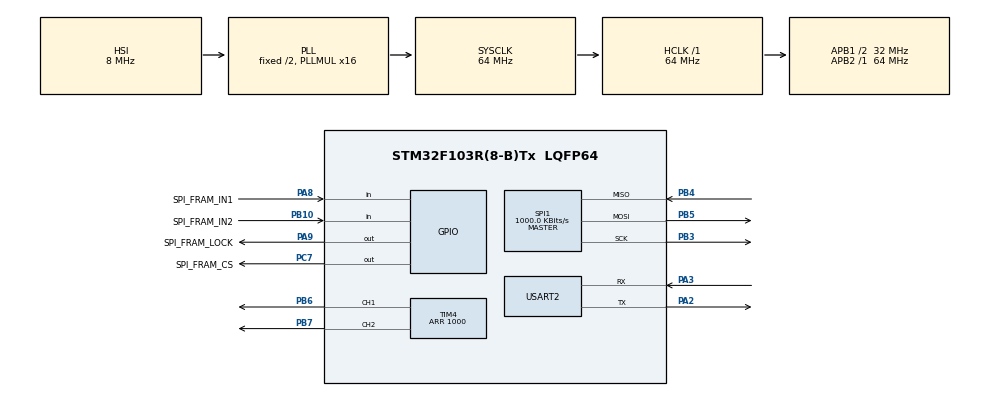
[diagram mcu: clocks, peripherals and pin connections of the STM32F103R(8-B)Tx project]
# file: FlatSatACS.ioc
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Mcu.Family=STM32F1
Mcu.Name=STM32F103R(8-B)Tx
Mcu.Package=LQFP64
NVIC.PriorityGroup=NVIC_PRIORITYGROUP_4
PA2.Mode=Asynchronous
PA2.Signal=USART2_TX
PA3.Mode=Asynchronous
PA3.Signal=USART2_RX
PA8.GPIO_Label=SPI_FRAM_IN1
PA8.Signal=GPIO_Input
PA9.GPIO_Label=SPI_FRAM_LOCK
PA9.Signal=GPIO_Output
PB10.GPIO_Label=SPI_FRAM_IN2
PB10.Signal=GPIO_Input
PB3.Mode=Full_Duplex_Master
PB3.Signal=SPI1_SCK
PB4.Mode=Full_Duplex_Master
PB4.Signal=SPI1_MISO
PB5.Mode=Full_Duplex_Master
PB5.Signal=SPI1_MOSI
PB6.Signal=S_TIM4_CH1
PB7.Signal=S_TIM4_CH2
PC7.GPIO_Label=SPI_FRAM_CS
PC7.Signal=GPIO_Output
ProjectManager.HeapSize=0x2000
ProjectManager.StackSize=0x400
ProjectManager.TargetToolchain=MDK-ARM V5
RCC.AHBFreq_Value=64000000
RCC.APB1CLKDivider=RCC_HCLK_DIV2
RCC.APB1Freq_Value=32000000
RCC.APB1TimFreq_Value=64000000
RCC.APB2Freq_Value=64000000
RCC.APB2TimFreq_Value=64000000
RCC.HCLKFreq_Value=64000000
RCC.PLLMUL=RCC_PLL_MUL16
RCC.RTCClockSelection=RCC_RTCCLKSOURCE_LSE
RCC.SYSCLKFreq_VALUE=64000000
RCC.SYSCLKSource=RCC_SYSCLKSOURCE_PLLCLK
RCC.USBFreq_Value=64000000
SH.S_TIM4_CH1.0=TIM4_CH1,PWM Generation1 CH1
SH.S_TIM4_CH2.0=TIM4_CH2,PWM Generation2 CH2
SPI1.BaudRatePrescaler=SPI_BAUDRATEPRESCALER_64
SPI1.CalculateBaudRate=1000.0 KBits/s
SPI1.Direction=SPI_DIRECTION_2LINES
SPI1.Mode=SPI_MODE_MASTER
SPI1.VirtualType=VM_MASTER
TIM4.Channel-PWM\ Generation1\ CH1=TIM_CHANNEL_1
TIM4.Channel-PWM\ Generation2\ CH2=TIM_CHANNEL_2
TIM4.Period=1000
TIM4.Pulse-PWM\ Generation1\ CH1=500
TIM4.Pulse-PWM\ Generation2\ CH2=500
USART2.VirtualMode=VM_ASYNC
VP_SYS_VS_ND.Mode=No_Debug
VP_TIM4_VS_ClockSourceINT.Mode=Internal
board=NUCLEO-F103RB

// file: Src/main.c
/* USER CODE BEGIN Header */
/**
  ******************************************************************************
  * @file           : main.c
  * @brief          : Main program body
  ******************************************************************************
  * @attention
  *
  * <h2><center>&copy; Copyright (c) 2019 STMicroelectronics.
  * All rights reserved.</center></h2>
  *
  * This software component is licensed by ST under BSD 3-Clause license,
  * the "License"; You may not use this file except in compliance with the
  * License. You may obtain a copy of the License at:
  *                        opensource.org/licenses/BSD-3-Clause
  *
  ******************************************************************************
  */
/* USER CODE END Header */

#include "main.h"

/* USER CODE BEGIN Includes */
#include <ACSStateMachine.h>
/* USER CODE END Includes */

SPI_HandleTypeDef hspi1;

TIM_HandleTypeDef htim4;

UART_HandleTypeDef huart2;

void SystemClock_Config(void);
static void MX_GPIO_Init(void);
static void MX_USART2_UART_Init(void);
static void MX_SPI1_Init(void);
static void MX_TIM4_Init(void);

int main(void)
{

  /* MCU Configuration--------------------------------------------------------*/

  /* Reset of all peripherals, Initializes the Flash interface and the Systick. */
  HAL_Init();

  /* Configure the system clock */
  SystemClock_Config();

  /* Initialize all configured peripherals */
  MX_GPIO_Init();
  MX_USART2_UART_Init();
  MX_SPI1_Init();
  MX_TIM4_Init();
  /* USER CODE BEGIN 2 */

	// Set global handles to allow the ACS to access them
	setUartHandle(&huart2);
	setSpiHandle(&hspi1);

	// Run the ACS main loop
	runACS();

  /* USER CODE END 2 */

  /* Infinite loop */

}

void SystemClock_Config(void)
{
  RCC_OscInitTypeDef RCC_OscInitStruct = {0};
  RCC_ClkInitTypeDef RCC_ClkInitStruct = {0};

  /** Initializes the CPU, AHB and APB busses clocks
  */
  RCC_OscInitStruct.OscillatorType = RCC_OSCILLATORTYPE_HSI;
  RCC_OscInitStruct.HSIState = RCC_HSI_ON;
  RCC_OscInitStruct.HSICalibrationValue = RCC_HSICALIBRATION_DEFAULT;
  RCC_OscInitStruct.PLL.PLLState = RCC_PLL_ON;
  RCC_OscInitStruct.PLL.PLLSource = RCC_PLLSOURCE_HSI_DIV2;
  RCC_OscInitStruct.PLL.PLLMUL = RCC_PLL_MUL16;
  if (HAL_RCC_OscConfig(&RCC_OscInitStruct) != HAL_OK)
  {
    Error_Handler();
  }
  /** Initializes the CPU, AHB and APB busses clocks
  */
  RCC_ClkInitStruct.ClockType = RCC_CLOCKTYPE_HCLK|RCC_CLOCKTYPE_SYSCLK
                              |RCC_CLOCKTYPE_PCLK1|RCC_CLOCKTYPE_PCLK2;
  RCC_ClkInitStruct.SYSCLKSource = RCC_SYSCLKSOURCE_PLLCLK;
  RCC_ClkInitStruct.AHBCLKDivider = RCC_SYSCLK_DIV1;
  RCC_ClkInitStruct.APB1CLKDivider = RCC_HCLK_DIV2;
  RCC_ClkInitStruct.APB2CLKDivider = RCC_HCLK_DIV1;

  if (HAL_RCC_ClockConfig(&RCC_ClkInitStruct, FLASH_LATENCY_2) != HAL_OK)
  {
    Error_Handler();
  }
}

static void MX_SPI1_Init(void)
{

  /* SPI1 parameter configuration*/
  hspi1.Instance = SPI1;
  hspi1.Init.Mode = SPI_MODE_MASTER;
  hspi1.Init.Direction = SPI_DIRECTION_2LINES;
  hspi1.Init.DataSize = SPI_DATASIZE_8BIT;
  hspi1.Init.CLKPolarity = SPI_POLARITY_LOW;
  hspi1.Init.CLKPhase = SPI_PHASE_1EDGE;
  hspi1.Init.NSS = SPI_NSS_SOFT;
  hspi1.Init.BaudRatePrescaler = SPI_BAUDRATEPRESCALER_64;
  hspi1.Init.FirstBit = SPI_FIRSTBIT_MSB;
  hspi1.Init.TIMode = SPI_TIMODE_DISABLE;
  hspi1.Init.CRCCalculation = SPI_CRCCALCULATION_DISABLE;
  hspi1.Init.CRCPolynomial = 10;
  if (HAL_SPI_Init(&hspi1) != HAL_OK)
  {
    Error_Handler();
  }

}

static void MX_TIM4_Init(void)
{

  TIM_ClockConfigTypeDef sClockSourceConfig = {0};
  TIM_MasterConfigTypeDef sMasterConfig = {0};
  TIM_OC_InitTypeDef sConfigOC = {0};

  htim4.Instance = TIM4;
  htim4.Init.Prescaler = 0;
  htim4.Init.CounterMode = TIM_COUNTERMODE_UP;
  htim4.Init.Period = 1000;
  htim4.Init.ClockDivision = TIM_CLOCKDIVISION_DIV1;
  htim4.Init.AutoReloadPreload = TIM_AUTORELOAD_PRELOAD_DISABLE;
  if (HAL_TIM_Base_Init(&htim4) != HAL_OK)
  {
    Error_Handler();
  }
  sClockSourceConfig.ClockSource = TIM_CLOCKSOURCE_INTERNAL;
  if (HAL_TIM_ConfigClockSource(&htim4, &sClockSourceConfig) != HAL_OK)
  {
    Error_Handler();
  }
  if (HAL_TIM_PWM_Init(&htim4) != HAL_OK)
  {
    Error_Handler();
  }
  sMasterConfig.MasterOutputTrigger = TIM_TRGO_RESET;
  sMasterConfig.MasterSlaveMode = TIM_MASTERSLAVEMODE_DISABLE;
  if (HAL_TIMEx_MasterConfigSynchronization(&htim4, &sMasterConfig) != HAL_OK)
  {
    Error_Handler();
  }
  sConfigOC.OCMode = TIM_OCMODE_PWM1;
  sConfigOC.Pulse = 500;
  sConfigOC.OCPolarity = TIM_OCPOLARITY_HIGH;
  sConfigOC.OCFastMode = TIM_OCFAST_DISABLE;
  if (HAL_TIM_PWM_ConfigChannel(&htim4, &sConfigOC, TIM_CHANNEL_1) != HAL_OK)
  {
    Error_Handler();
  }
  if (HAL_TIM_PWM_ConfigChannel(&htim4, &sConfigOC, TIM_CHANNEL_2) != HAL_OK)
  {
    Error_Handler();
  }
  HAL_TIM_MspPostInit(&htim4);

}

static void MX_USART2_UART_Init(void)
{

  huart2.Instance = USART2;
  huart2.Init.BaudRate = 115200;
  huart2.Init.WordLength = UART_WORDLENGTH_8B;
  huart2.Init.StopBits = UART_STOPBITS_1;
  huart2.Init.Parity = UART_PARITY_NONE;
  huart2.Init.Mode = UART_MODE_TX_RX;
  huart2.Init.HwFlowCtl = UART_HWCONTROL_NONE;
  huart2.Init.OverSampling = UART_OVERSAMPLING_16;
  if (HAL_UART_Init(&huart2) != HAL_OK)
  {
    Error_Handler();
  }

}

static void MX_GPIO_Init(void)
{

  /* GPIO Ports Clock Enable */
  __HAL_RCC_GPIOA_CLK_ENABLE();
  __HAL_RCC_GPIOB_CLK_ENABLE();

}

void Error_Handler(void)
{
}

/************************ (C) COPYRIGHT STMicroelectronics *****END OF FILE****/
